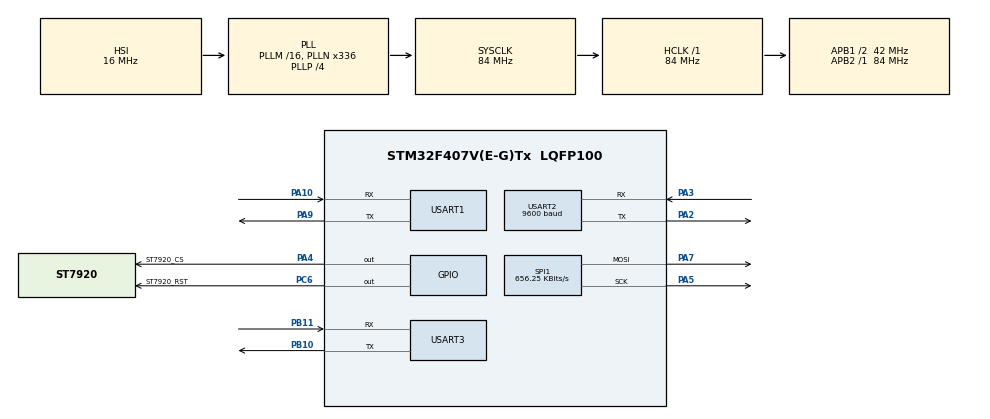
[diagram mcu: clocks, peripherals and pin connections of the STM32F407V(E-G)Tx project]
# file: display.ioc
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FREERTOS.Tasks01=defaultTask,24,128,StartDefaultTask,Default,NULL,Dynamic,NULL,NULL
FREERTOS.configRECORD_STACK_HIGH_ADDRESS=1
FREERTOS.configUSE_NEWLIB_REENTRANT=1
Mcu.Family=STM32F4
Mcu.Name=STM32F407V(E-G)Tx
Mcu.Package=LQFP100
NVIC.PriorityGroup=NVIC_PRIORITYGROUP_4
NVIC.TIM1_UP_TIM10_IRQn=true\:15\:0\:false\:false\:true\:false\:false\:true\:true
NVIC.TimeBase=TIM1_UP_TIM10_IRQn
NVIC.TimeBaseIP=TIM1
PA10.Mode=Asynchronous
PA10.Signal=USART1_RX
PA13.Mode=Serial_Wire
PA13.Signal=SYS_JTMS-SWDIO
PA14.Mode=Serial_Wire
PA14.Signal=SYS_JTCK-SWCLK
PA2.Mode=Asynchronous
PA2.Signal=USART2_TX
PA3.Mode=Asynchronous
PA3.Signal=USART2_RX
PA4.GPIO_Label=ST7920_CS
PA4.PinState=GPIO_PIN_SET
PA4.Signal=GPIO_Output
PA5.Mode=TX_Only_Simplex_Unidirect_Master
PA5.Signal=SPI1_SCK
PA7.Mode=TX_Only_Simplex_Unidirect_Master
PA7.Signal=SPI1_MOSI
PA9.Mode=Asynchronous
PA9.Signal=USART1_TX
PB10.Mode=Asynchronous
PB10.Signal=USART3_TX
PB11.Mode=Asynchronous
PB11.Signal=USART3_RX
PC6.GPIO_Label=ST7920_RST
PC6.PinState=GPIO_PIN_SET
PC6.Signal=GPIO_Output
ProjectManager.HeapSize=0x200
ProjectManager.StackSize=0x400
ProjectManager.TargetToolchain=STM32CubeIDE
RCC.48MHZClocksFreq_Value=84000000
RCC.AHBFreq_Value=84000000
RCC.APB1CLKDivider=RCC_HCLK_DIV2
RCC.APB1Freq_Value=42000000
RCC.APB1TimFreq_Value=84000000
RCC.APB2Freq_Value=84000000
RCC.APB2TimFreq_Value=84000000
RCC.CortexFreq_Value=84000000
RCC.EnableHSERTCDevisor-ClockTree=true
RCC.HCLKFreq_Value=84000000
RCC.HSE_VALUE=25000000
RCC.HSI_VALUE=16000000
RCC.LSE_VALUE=32768
RCC.PLLN=336
RCC.PLLP=RCC_PLLP_DIV4
RCC.SYSCLKFreq_VALUE=84000000
RCC.SYSCLKSource=RCC_SYSCLKSOURCE_PLLCLK
RCC.VCOOutputFreq_Value=336000000
SPI1.BaudRatePrescaler=SPI_BAUDRATEPRESCALER_128
SPI1.CLKPhase=SPI_PHASE_2EDGE
SPI1.CLKPolarity=SPI_POLARITY_HIGH
SPI1.CalculateBaudRate=656.25 KBits/s
SPI1.Direction=SPI_DIRECTION_2LINES
SPI1.Mode=SPI_MODE_MASTER
SPI1.VirtualType=VM_MASTER
USART1.VirtualMode=VM_ASYNC
USART2.BaudRate=9600
USART2.VirtualMode=VM_ASYNC
USART3.VirtualMode=VM_ASYNC
VP_FREERTOS_VS_CMSIS_V2.Mode=CMSIS_V2
VP_SYS_VS_tim1.Mode=TIM1
board=custom

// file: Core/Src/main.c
/* USER CODE BEGIN Header */
/**
  ******************************************************************************
  * @file           : main.c
  * @brief          : Main program body
  ******************************************************************************
  * @attention
  *
  * Copyright (c) 2026 STMicroelectronics.
  * All rights reserved.
  *
  * This software is licensed under terms that can be found in the LICENSE file
  * in the root directory of this software component.
  * If no LICENSE file comes with this software, it is provided AS-IS.
  *
  ******************************************************************************
  */
/* USER CODE END Header */
#include "main.h"
#include "cmsis_os.h"
#include "st7920.h"
#include "sensor.h"
//#include "lte_4g.h"
#include <stdio.h>
#include <string.h>

SPI_HandleTypeDef hspi1;

UART_HandleTypeDef huart1;
UART_HandleTypeDef huart2;
UART_HandleTypeDef huart3;

/* Definitions for defaultTask */
//osThreadId_t defaultTaskHandle;
//const osThreadAttr_t defaultTask_attributes = {
//  .name = "defaultTask",
//  .stack_size = 128 * 4,
//  .priority = (osPriority_t) osPriorityNormal,
//};
/* ── Queue ───────────────────────────────────────────────────── */
osMessageQueueId_t sensor_queue;

/* ── Task Attributes ─────────────────────────────────────────── */
const osThreadAttr_t sensor_task_attr = {
    .name       = "sensor_task",
    .stack_size = 512 * 4,
    .priority   = osPriorityAboveNormal,
};

const osThreadAttr_t display_task_attr = {
    .name       = "display_task",
    .stack_size = 512 * 4,
    .priority   = osPriorityNormal,
};

/* lte_task_attr — uncomment setelah hardware tersedia */
/*
const osThreadAttr_t lte_task_attr = {
    .name       = "lte_task",
    .stack_size = 1024 * 4,
    .priority   = osPriorityBelowNormal,
};
*/
//static void debug_print(const char *msg)
//{
//    HAL_UART_Transmit(&huart1, (uint8_t *)msg, strlen(msg), 100);
//}

void SystemClock_Config(void);
static void MX_GPIO_Init(void);
static void MX_SPI1_Init(void);
static void MX_USART1_UART_Init(void);
static void MX_USART2_UART_Init(void);
static void MX_USART3_UART_Init(void);
void StartDefaultTask(void *argument);

/* USER CODE BEGIN PFP */
void sensor_task(void *arg);
void display_task(void *arg);
/* USER CODE END PFP */

int main(void)
{

  /* MCU Configuration--------------------------------------------------------*/

  /* Reset of all peripherals, Initializes the Flash interface and the Systick. */
  HAL_Init();

  /* Configure the system clock */
  SystemClock_Config();

  /* Initialize all configured peripherals */
  MX_GPIO_Init();
  MX_SPI1_Init();
  MX_USART1_UART_Init();
  MX_USART2_UART_Init();
  MX_USART3_UART_Init();

  /* Init scheduler */
  osKernelInitialize();

  /* USER CODE BEGIN RTOS_QUEUES */
  /* add queues, ... */
  sensor_queue = osMessageQueueNew(1, sizeof(sensor_data_t), NULL);
  /* USER CODE END RTOS_QUEUES */

  /* Create the thread(s) */
  /* creation of defaultTask */
//  defaultTaskHandle = osThreadNew(StartDefaultTask, NULL, &defaultTask_attributes);
  osThreadNew(sensor_task,  NULL, &sensor_task_attr);
  osThreadNew(display_task, NULL, &display_task_attr);

  /* Start scheduler */
  osKernelStart();

  /* We should never get here as control is now taken by the scheduler */

  /* Infinite loop */
  while (1)
  {

  }
}

void SystemClock_Config(void)
{
  RCC_OscInitTypeDef RCC_OscInitStruct = {0};
  RCC_ClkInitTypeDef RCC_ClkInitStruct = {0};

  /** Configure the main internal regulator output voltage
  */
  __HAL_RCC_PWR_CLK_ENABLE();
  __HAL_PWR_VOLTAGESCALING_CONFIG(PWR_REGULATOR_VOLTAGE_SCALE1);

  /** Initializes the RCC Oscillators according to the specified parameters
  * in the RCC_OscInitTypeDef structure.
  */
  RCC_OscInitStruct.OscillatorType = RCC_OSCILLATORTYPE_HSI;
  RCC_OscInitStruct.HSIState = RCC_HSI_ON;
  RCC_OscInitStruct.HSICalibrationValue = RCC_HSICALIBRATION_DEFAULT;
  RCC_OscInitStruct.PLL.PLLState = RCC_PLL_ON;
  RCC_OscInitStruct.PLL.PLLSource = RCC_PLLSOURCE_HSI;
  RCC_OscInitStruct.PLL.PLLM = 16;
  RCC_OscInitStruct.PLL.PLLN = 336;
  RCC_OscInitStruct.PLL.PLLP = RCC_PLLP_DIV4;
  RCC_OscInitStruct.PLL.PLLQ = 4;
  if (HAL_RCC_OscConfig(&RCC_OscInitStruct) != HAL_OK)
  {
    Error_Handler();
  }

  /** Initializes the CPU, AHB and APB buses clocks
  */
  RCC_ClkInitStruct.ClockType = RCC_CLOCKTYPE_HCLK|RCC_CLOCKTYPE_SYSCLK
                              |RCC_CLOCKTYPE_PCLK1|RCC_CLOCKTYPE_PCLK2;
  RCC_ClkInitStruct.SYSCLKSource = RCC_SYSCLKSOURCE_PLLCLK;
  RCC_ClkInitStruct.AHBCLKDivider = RCC_SYSCLK_DIV1;
  RCC_ClkInitStruct.APB1CLKDivider = RCC_HCLK_DIV2;
  RCC_ClkInitStruct.APB2CLKDivider = RCC_HCLK_DIV1;

  if (HAL_RCC_ClockConfig(&RCC_ClkInitStruct, FLASH_LATENCY_2) != HAL_OK)
  {
    Error_Handler();
  }
}

static void MX_SPI1_Init(void)
{

  /* SPI1 parameter configuration*/
  hspi1.Instance = SPI1;
  hspi1.Init.Mode = SPI_MODE_MASTER;
  hspi1.Init.Direction = SPI_DIRECTION_2LINES;
  hspi1.Init.DataSize = SPI_DATASIZE_8BIT;
  hspi1.Init.CLKPolarity = SPI_POLARITY_HIGH;
  hspi1.Init.CLKPhase = SPI_PHASE_2EDGE;
  hspi1.Init.NSS = SPI_NSS_SOFT;
  hspi1.Init.BaudRatePrescaler = SPI_BAUDRATEPRESCALER_128;
  hspi1.Init.FirstBit = SPI_FIRSTBIT_MSB;
  hspi1.Init.TIMode = SPI_TIMODE_DISABLE;
  hspi1.Init.CRCCalculation = SPI_CRCCALCULATION_DISABLE;
  hspi1.Init.CRCPolynomial = 10;
  if (HAL_SPI_Init(&hspi1) != HAL_OK)
  {
    Error_Handler();
  }

}

static void MX_USART1_UART_Init(void)
{

  huart1.Instance = USART1;
  huart1.Init.BaudRate = 115200;
  huart1.Init.WordLength = UART_WORDLENGTH_8B;
  huart1.Init.StopBits = UART_STOPBITS_1;
  huart1.Init.Parity = UART_PARITY_NONE;
  huart1.Init.Mode = UART_MODE_TX_RX;
  huart1.Init.HwFlowCtl = UART_HWCONTROL_NONE;
  huart1.Init.OverSampling = UART_OVERSAMPLING_16;
  if (HAL_UART_Init(&huart1) != HAL_OK)
  {
    Error_Handler();
  }

}

static void MX_USART2_UART_Init(void)
{

  huart2.Instance = USART2;
  huart2.Init.BaudRate = 9600;
  huart2.Init.WordLength = UART_WORDLENGTH_8B;
  huart2.Init.StopBits = UART_STOPBITS_1;
  huart2.Init.Parity = UART_PARITY_NONE;
  huart2.Init.Mode = UART_MODE_TX_RX;
  huart2.Init.HwFlowCtl = UART_HWCONTROL_NONE;
  huart2.Init.OverSampling = UART_OVERSAMPLING_16;
  if (HAL_UART_Init(&huart2) != HAL_OK)
  {
    Error_Handler();
  }

}

static void MX_USART3_UART_Init(void)
{

  huart3.Instance = USART3;
  huart3.Init.BaudRate = 115200;
  huart3.Init.WordLength = UART_WORDLENGTH_8B;
  huart3.Init.StopBits = UART_STOPBITS_1;
  huart3.Init.Parity = UART_PARITY_NONE;
  huart3.Init.Mode = UART_MODE_TX_RX;
  huart3.Init.HwFlowCtl = UART_HWCONTROL_NONE;
  huart3.Init.OverSampling = UART_OVERSAMPLING_16;
  if (HAL_UART_Init(&huart3) != HAL_OK)
  {
    Error_Handler();
  }

}

static void MX_GPIO_Init(void)
{
  GPIO_InitTypeDef GPIO_InitStruct = {0};

  /* GPIO Ports Clock Enable */
  __HAL_RCC_GPIOA_CLK_ENABLE();
  __HAL_RCC_GPIOB_CLK_ENABLE();
  __HAL_RCC_GPIOC_CLK_ENABLE();

  /*Configure GPIO pin Output Level */
  HAL_GPIO_WritePin(ST7920_CS_GPIO_Port, ST7920_CS_Pin, GPIO_PIN_SET);

  /*Configure GPIO pin Output Level */
  HAL_GPIO_WritePin(ST7920_RST_GPIO_Port, ST7920_RST_Pin, GPIO_PIN_SET);

  /*Configure GPIO pin : ST7920_CS_Pin */
  GPIO_InitStruct.Pin = ST7920_CS_Pin;
  GPIO_InitStruct.Mode = GPIO_MODE_OUTPUT_PP;
  GPIO_InitStruct.Pull = GPIO_NOPULL;
  GPIO_InitStruct.Speed = GPIO_SPEED_FREQ_LOW;
  HAL_GPIO_Init(ST7920_CS_GPIO_Port, &GPIO_InitStruct);

  /*Configure GPIO pin : ST7920_RST_Pin */
  GPIO_InitStruct.Pin = ST7920_RST_Pin;
  GPIO_InitStruct.Mode = GPIO_MODE_OUTPUT_PP;
  GPIO_InitStruct.Pull = GPIO_NOPULL;
  GPIO_InitStruct.Speed = GPIO_SPEED_FREQ_LOW;
  HAL_GPIO_Init(ST7920_RST_GPIO_Port, &GPIO_InitStruct);

}

/* USER CODE BEGIN Header_StartDefaultTask */
///**
//  * @brief  Function implementing the defaultTask thread.
//  * @param  argument: Not used
//  * @retval None
//  */
/* USER CODE END Header_StartDefaultTask */
//void StartDefaultTask(void *argument)
//{
  /* USER CODE BEGIN 5 */
////  /* Infinite loop */
////  for(;;)
////  {
////    osDelay(1);
////  }
  /* USER CODE END 5 */
//}

/* ══════════════════════════════════════════════════════════════
 * sensor_task
 * Baca XY-MD02 setiap 5 detik, kirim ke queue
 * ══════════════════════════════════════════════════════════════ */
void sensor_task(void *arg)
{
    sensor_data_t data;
    sensor_init();

    while (1)
    {
        int ret = sensor_read(&data);

        if (ret == SENSOR_OK)
        {
            /* Overwrite queue dengan data terbaru */
            osMessageQueuePut(sensor_queue, &data, 0, 0);
        }
        /* Debug via USART1 */
        char dbg[64];
                snprintf(dbg, sizeof(dbg),
                         "[SENSOR] ret=%d T=%.1f H=%.1f\r\n",
                         ret, data.temperature, data.humidity);
                HAL_UART_Transmit(&huart1, (uint8_t*)dbg, strlen(dbg), 100);

        osDelay(5000);
    }
}

/* ══════════════════════════════════════════════════════════════
 * display_task
 * Update ST7920 setiap 500ms dengan data terbaru dari queue
 * ══════════════════════════════════════════════════════════════ */
void display_task(void *arg)
{
    sensor_data_t data = {0};
    char buf[32];

    ST7920_Init();

    while (1)
    {
        /* Ambil data dari queue, non-blocking */
        osMessageQueueGet(sensor_queue, &data, NULL, 0);

        ST7920_ClearBuffer();

        /* ── Header ── */
        ST7920_DrawStr(0, 0, "STM32 Monitor");
        ST7920_DrawHLine(0, 10, 128, 1);

        /* ── Sensor data ── */
        if (data.valid)
        {
            snprintf(buf, sizeof(buf), "Temp : %.1f C", data.temperature);
            ST7920_DrawStr(0, 14, buf);

            snprintf(buf, sizeof(buf), "Humi : %.1f %%", data.humidity);
            ST7920_DrawStr(0, 26, buf);
        }
        else
        {
            ST7920_DrawStr(0, 14, "Sensor: waiting..");
        }

        /* ── LTE status (placeholder) ── */
        ST7920_DrawHLine(0, 40, 128, 1);
        ST7920_DrawStr(0, 44, "LTE : --");
        ST7920_DrawStr(0, 54, "MQTT: --");

        ST7920_SendBuffer();

        osDelay(500);
    }
}

void HAL_TIM_PeriodElapsedCallback(TIM_HandleTypeDef *htim)
{
  if (htim->Instance == TIM1)
  {
    HAL_IncTick();
  }
}

void Error_Handler(void)
{
  __disable_irq();
  while (1)
  {
  }
}
